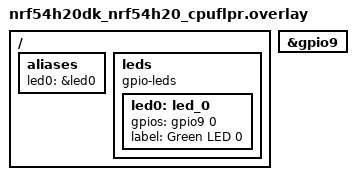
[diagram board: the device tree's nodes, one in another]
/* SPDX-License-Identifier: Apache-2.0 */

/ {
	aliases {
		led0 = &led0;
	};

	leds {
		compatible = "gpio-leds";

		led0: led_0 {
			gpios = <&gpio9 0 GPIO_ACTIVE_HIGH>;
			label = "Green LED 0";
		};
	};
};

&gpio9 {
	status = "okay";
};
